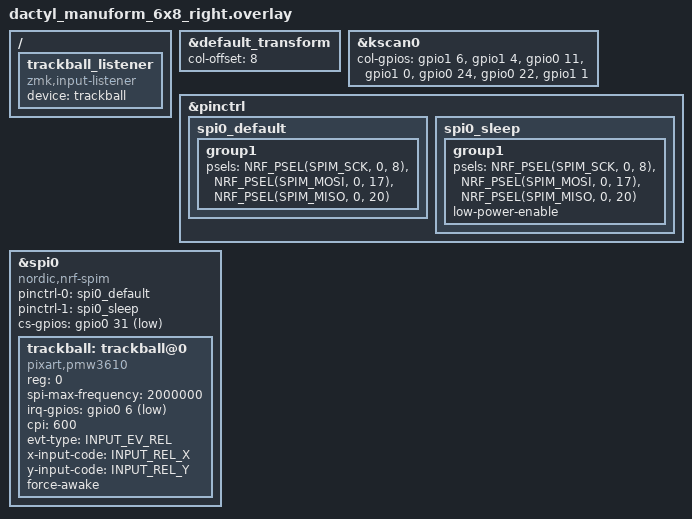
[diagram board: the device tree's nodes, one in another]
#include "dactyl_manuform_6x8.dtsi"

&default_transform { // The matrix transform for this board is 8 columns over because the left half is 8 columns wide according to the matrix.
    col-offset = <8>;
};

&kscan0 {
    col-gpios
        = <&gpio1 6 GPIO_ACTIVE_HIGH>
        , <&gpio1 4 GPIO_ACTIVE_HIGH>
        , <&gpio0 11 GPIO_ACTIVE_HIGH>
        , <&gpio1 0 GPIO_ACTIVE_HIGH>
        , <&gpio0 24 GPIO_ACTIVE_HIGH>
		, <&gpio0 22 GPIO_ACTIVE_HIGH>
		, <&gpio1 1 GPIO_ACTIVE_HIGH>
        ;
};

// mouse / pointing device
&pinctrl {
    spi0_default: spi0_default {
        group1 {
            psels = <NRF_PSEL(SPIM_SCK, 0, 8)>,
                <NRF_PSEL(SPIM_MOSI, 0, 17)>,
                <NRF_PSEL(SPIM_MISO, 0, 20)>;
        };
    };

    spi0_sleep: spi0_sleep {
        group1 {
            psels = <NRF_PSEL(SPIM_SCK, 0, 8)>,
                <NRF_PSEL(SPIM_MOSI, 0, 17)>,
                <NRF_PSEL(SPIM_MISO, 0, 20)>;
            low-power-enable;
        };
    };
};

#include <zephyr/dt-bindings/input/input-event-codes.h>

&spi0 {
    status = "okay";
    compatible = "nordic,nrf-spim";
    pinctrl-0 = <&spi0_default>;
    pinctrl-1 = <&spi0_sleep>;
    pinctrl-names = "default", "sleep";
    cs-gpios = <&gpio0 31 GPIO_ACTIVE_LOW>;

    trackball: trackball@0 {
        status = "okay";
        compatible = "pixart,pmw3610";
        reg = <0>;
        spi-max-frequency = <2000000>;
        irq-gpios = <&gpio0 6 (GPIO_ACTIVE_LOW | GPIO_PULL_UP)>;
        cpi = <600>;
        evt-type = <INPUT_EV_REL>;
        x-input-code = <INPUT_REL_X>;
        y-input-code = <INPUT_REL_Y>;

        force-awake;
        /* keep the sensor awake while ZMK activity state is ACTIVE,
           fallback to normal downshift mode after ZMK goes into IDLE / SLEEP mode.
           thus, the sensor would be a `wakeup-source` */
    };
};

/ {
  trackball_listener {
    compatible = "zmk,input-listener";
    device = <&trackball>;
  };
};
